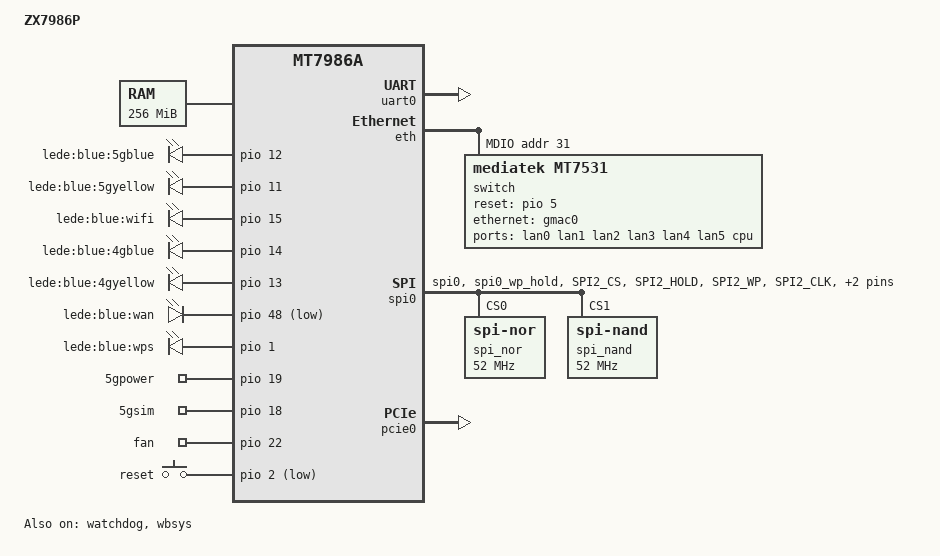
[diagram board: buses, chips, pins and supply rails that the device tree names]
/dts-v1/;
#include "mt7986a.dtsi"
#include "mt7986a-pinctrl.dtsi"
#include <dt-bindings/input/input.h>

/ {
	model = "ZX7986P";
	compatible = "ZX7986P";
	chosen {
		bootargs = "console=ttyS0,115200n1 loglevel=8  \
				earlycon=uart8250,mmio32,0x11002000";
	};

	memory {
		reg = <0 0x40000000 0 0x10000000>;
	};

	gpio-leds {
		compatible = "gpio-leds";

		5gblue {
			label = "lede:blue:5gblue";
			gpios = <&pio 12 0>;
			linux,default-trigger = "none";
			default-state = "off";
		};

		5gyellow {
			label = "lede:blue:5gyellow";
			gpios = <&pio 11 0>;
			linux,default-trigger = "none";
			default-state = "off";
		};

		wifi {
			label = "lede:blue:wifi";
			gpios = <&pio 15 0>;
			linux,default-trigger = "none";
			default-state = "off";
		};

		4gblue {
			label = "lede:blue:4gblue";
			gpios = <&pio 14 0>;
			linux,default-trigger = "none";
			default-state = "off";
		};

		4gyellow {
			label = "lede:blue:4gyellow";
			gpios = <&pio 13 0>;
			linux,default-trigger = "none";
			default-state = "off";
		};

		wan {
			label = "lede:blue:wan";
			gpios = <&pio 48 1>;
			linux,default-trigger = "none";
			default-state = "off";
		};

		wps {
			label = "lede:blue:wps";
			gpios = <&pio 1 0>;
			linux,default-trigger = "none";
			default-state = "off";
		};
	};

	gpio-export {
		compatible = "gpio-export";
		5gpower {
			gpio-export,name = "5gpower";
			gpio-export,output = <0>; // OUT_INIT_LOW
			gpios = <&pio 19 0>;    // GPIO 19, ACTIVE_LOW
		};

		5gsim {
			gpio-export,name = "5gsim";
			gpio-export,output = <1>; // OUT_INIT_LOW
			gpios = <&pio 18 0>;    // GPIO 18, ACTIVE_LOW
		};

		fan {
			gpio-export,name = "fan";
			gpio-export,output = <1>; // OUT_INIT_LOW
			gpios = <&pio 22 0>;    // GPIO 22, ACTIVE_LOW
		};
	};

	gpio-keys {
		compatible = "gpio-keys";
		#address-cells = <1>;
		#size-cells = <0>;
		poll-interval = <20>;

		reset {
			label = "reset";
			gpios = <&pio 2 1>;
			linux,code = <KEY_RESTART>;
		};
	};

	nmbm_spim_nand {
		compatible = "generic,nmbm";

		#address-cells = <1>;
		#size-cells = <1>;

		lower-mtd-device = <&spi_nand>;
		forced-create;

		partitions {
			compatible = "fixed-partitions";
			#address-cells = <1>;
			#size-cells = <1>;

			partition@0 {
				label = "BL2";
				reg = <0x00000 0x0100000>;
			};

			partition@100000 {
				label = "u-boot-env";
				reg = <0x0100000 0x0080000>;
			};

			factory: partition@180000 {
				label = "Factory";
				reg = <0x180000 0x0200000>;
			};

			partition@380000 {
				label = "FIP";
				reg = <0x380000 0x0200000>;
			};

			partition@580000 {
				label = "woem";
				reg = <0x580000 0xa0000>;
			};

			partition@620000 {
				label = "ubi";
				reg = <0x620000 0x3800000>;
			};

			partition@3E20000 {
				label = "ubi2";
				reg = <0x3E20000 0x3800000>;
			};

			partition@7620000 {
				label = "wtinfo";
				reg = <0x7620000 0x60000>;
			};

			partition@7680000 {
				label = "nvram";
				reg = <0x7680000 0x60000>;
			};
		};
	};
};

/*&pwm {
	pinctrl-names = "default";
	pinctrl-0 = <&pwm0_pin &pwm1_pin_g1>;
	status = "disabled";
};*/

&uart0 {
	status = "okay";
};

&watchdog {
	status = "okay";
};

&eth {
	status = "okay";

	gmac0: mac@0 {
		compatible = "mediatek,eth-mac";
		reg = <0>;
		phy-mode = "2500base-x";

		fixed-link {
			speed = <2500>;
			full-duplex;
			pause;
		};
	};

	gmac1: mac@1 {
		compatible = "mediatek,eth-mac";
		reg = <1>;
		phy-mode = "2500base-x";

		fixed-link {
			speed = <2500>;
			full-duplex;
			pause;
		};
	};

	mdio: mdio-bus {
		#address-cells = <1>;
		#size-cells = <0>;

		reset-gpios = <&pio 6 1>;
		reset-delay-us = <600>;

		switch@0 {
			compatible = "mediatek,mt7531";
			reg = <31>;
			reset-gpios = <&pio 5 0>;

			ports {
				#address-cells = <1>;
				#size-cells = <0>;

				port@0 {
					reg = <0>;
					label = "lan0";
				};

				port@1 {
					reg = <1>;
					label = "lan1";
				};

				port@2 {
					reg = <2>;
					label = "lan2";
				};

				port@3 {
					reg = <3>;
					label = "lan3";
				};

				port@4 {
					reg = <4>;
					label = "lan4";
				};

				port@5 {
                	reg = <5>;
                    label = "lan5";
                    phy-mode = "2500base-x";
	                fixed-link {
        	                speed = <2500>;
                	        full-duplex;
                        	pause;
                    };
				};

				port@6 {
					reg = <6>;
					label = "cpu";
					ethernet = <&gmac0>;
					phy-mode = "2500base-x";

					fixed-link {
						speed = <2500>;
						full-duplex;
						pause;
					};
				};
			};
		};
	};
};

&hnat {
	mtketh-wan = "eth1";
	mtketh-lan = "lan";
	mtketh-max-gmac = <2>;
	status = "disabled";
};

&spi0 {
	pinctrl-names = "default";
	pinctrl-0 = <&spi_flash_pins>;
	cs-gpios = <0>, <0>;
	status = "okay";

	spi_nor@0 {
		#address-cells = <1>;
		#size-cells = <1>;
		compatible = "jedec,spi-nor";
		reg = <0>;
		spi-max-frequency = <52000000>;
		spi-tx-bus-width = <4>;
		spi-rx-bus-width = <4>;
	};

	spi_nand: spi_nand@1 {
		#address-cells = <1>;
		#size-cells = <1>;
		compatible = "spi-nand";
		reg = <1>;
		spi-max-frequency = <52000000>;
		spi-tx-bus-width = <4>;
		spi-rx-bus-width = <4>;
	};
};

&pcie0 {
	pinctrl-names = "default";
	pinctrl-0 = <&pcie0_pins>;
	status = "okay";
};

&wbsys {
	mediatek,mtd-eeprom = <&factory 0x0000>;
	status = "okay";
	pinctrl-names = "default", "dbdc";
	pinctrl-0 = <&wf_2g_5g_pins>;
	pinctrl-1 = <&wf_dbdc_pins>;
};

&pio {
	spi_flash_pins: spi-flash-pins-33-to-38 {
		mux {
			function = "flash";
			groups = "spi0", "spi0_wp_hold";
		};
		conf-pu {
			pins = "SPI2_CS", "SPI2_HOLD", "SPI2_WP";
			drive-strength = <MTK_DRIVE_8mA>;
			bias-pull-up = <MTK_PUPD_SET_R1R0_11>;
		};
		conf-pd {
			pins = "SPI2_CLK", "SPI2_MOSI", "SPI2_MISO";
			drive-strength = <MTK_DRIVE_8mA>;
			bias-pull-down = <MTK_PUPD_SET_R1R0_11>;
		};
	};

	wf_2g_5g_pins: wf_2g_5g-pins {
		mux {
			function = "wifi";
			groups = "wf_2g", "wf_5g";
		};
		conf {
			pins = "WF0_HB1", "WF0_HB2", "WF0_HB3", "WF0_HB4",
			       "WF0_HB0", "WF0_HB0_B", "WF0_HB5", "WF0_HB6",
			       "WF0_HB7", "WF0_HB8", "WF0_HB9", "WF0_HB10",
			       "WF0_TOP_CLK", "WF0_TOP_DATA", "WF1_HB1",
			       "WF1_HB2", "WF1_HB3", "WF1_HB4", "WF1_HB0",
			       "WF1_HB5", "WF1_HB6", "WF1_HB7", "WF1_HB8",
			       "WF1_TOP_CLK", "WF1_TOP_DATA";
			drive-strength = <MTK_DRIVE_4mA>;
		};
	};

	wf_dbdc_pins: wf_dbdc-pins {
		mux {
			function = "wifi";
			groups = "wf_dbdc";
		};
		conf {
			pins = "WF0_HB1", "WF0_HB2", "WF0_HB3", "WF0_HB4",
			       "WF0_HB0", "WF0_HB0_B", "WF0_HB5", "WF0_HB6",
			       "WF0_HB7", "WF0_HB8", "WF0_HB9", "WF0_HB10",
			       "WF0_TOP_CLK", "WF0_TOP_DATA", "WF1_HB1",
			       "WF1_HB2", "WF1_HB3", "WF1_HB4", "WF1_HB0",
			       "WF1_HB5", "WF1_HB6", "WF1_HB7", "WF1_HB8",
			       "WF1_TOP_CLK", "WF1_TOP_DATA";
			drive-strength = <MTK_DRIVE_4mA>;
		};
	};
};
